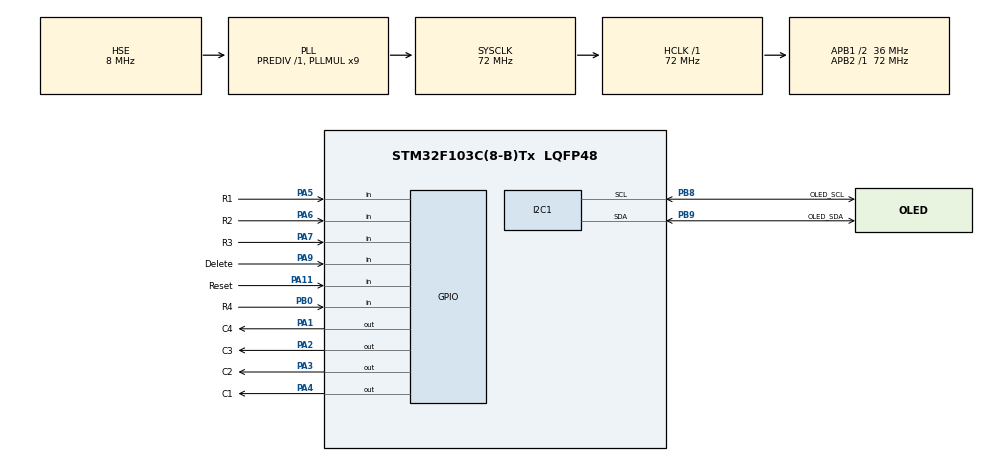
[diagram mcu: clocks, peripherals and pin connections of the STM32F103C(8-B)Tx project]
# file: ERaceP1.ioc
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I2C1.I2C_Mode=I2C_Fast
Mcu.Family=STM32F1
Mcu.Name=STM32F103C(8-B)Tx
Mcu.Package=LQFP48
NVIC.PriorityGroup=NVIC_PRIORITYGROUP_4
PA1.GPIO_Label=C4
PA1.GPIO_Speed=GPIO_SPEED_FREQ_HIGH
PA1.PinState=GPIO_PIN_SET
PA1.Signal=GPIO_Output
PA11.GPIO_Label=Reset
PA11.GPIO_PuPd=GPIO_PULLDOWN
PA11.Signal=GPIO_Input
PA13.Mode=Serial_Wire
PA13.Signal=SYS_JTMS-SWDIO
PA14.Mode=Serial_Wire
PA14.Signal=SYS_JTCK-SWCLK
PA2.GPIO_Label=C3
PA2.GPIO_Speed=GPIO_SPEED_FREQ_HIGH
PA2.PinState=GPIO_PIN_SET
PA2.Signal=GPIO_Output
PA3.GPIO_Label=C2
PA3.GPIO_Speed=GPIO_SPEED_FREQ_HIGH
PA3.PinState=GPIO_PIN_SET
PA3.Signal=GPIO_Output
PA4.GPIO_Label=C1
PA4.GPIO_Speed=GPIO_SPEED_FREQ_HIGH
PA4.PinState=GPIO_PIN_SET
PA4.Signal=GPIO_Output
PA5.GPIO_Label=R1
PA5.GPIO_PuPd=GPIO_PULLUP
PA5.Signal=GPIO_Input
PA6.GPIO_Label=R2
PA6.GPIO_PuPd=GPIO_PULLUP
PA6.Signal=GPIO_Input
PA7.GPIO_Label=R3
PA7.GPIO_PuPd=GPIO_PULLUP
PA7.Signal=GPIO_Input
PA9.GPIO_Label=Delete
PA9.GPIO_PuPd=GPIO_PULLDOWN
PA9.Signal=GPIO_Input
PB0.GPIO_Label=R4
PB0.GPIO_PuPd=GPIO_PULLUP
PB0.Signal=GPIO_Input
PB8.GPIO_Label=OLED_SCL
PB8.Mode=I2C
PB8.Signal=I2C1_SCL
PB9.GPIO_Label=OLED_SDA
PB9.Mode=I2C
PB9.Signal=I2C1_SDA
PC14-OSC32_IN.Mode=LSE-External-Oscillator
PC14-OSC32_IN.Signal=RCC_OSC32_IN
PC15-OSC32_OUT.Mode=LSE-External-Oscillator
PC15-OSC32_OUT.Signal=RCC_OSC32_OUT
PD0-OSC_IN.Mode=HSE-External-Oscillator
PD0-OSC_IN.Signal=RCC_OSC_IN
PD1-OSC_OUT.Mode=HSE-External-Oscillator
PD1-OSC_OUT.Signal=RCC_OSC_OUT
ProjectManager.HeapSize=0x200
ProjectManager.StackSize=0x400
ProjectManager.TargetToolchain=STM32CubeIDE
RCC.AHBFreq_Value=72000000
RCC.APB1CLKDivider=RCC_HCLK_DIV2
RCC.APB1Freq_Value=36000000
RCC.APB1TimFreq_Value=72000000
RCC.APB2Freq_Value=72000000
RCC.APB2TimFreq_Value=72000000
RCC.HCLKFreq_Value=72000000
RCC.PLLMUL=RCC_PLL_MUL9
RCC.PLLSourceVirtual=RCC_PLLSOURCE_HSE
RCC.SYSCLKFreq_VALUE=72000000
RCC.SYSCLKSource=RCC_SYSCLKSOURCE_PLLCLK
RCC.USBFreq_Value=72000000
board=custom

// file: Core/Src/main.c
/* USER CODE BEGIN Header */
/**
  ******************************************************************************
  * @file           : main.c
  * @brief          : Main program body
  ******************************************************************************
  * @attention
  *
  * Copyright (c) 2023 STMicroelectronics.
  * All rights reserved.
  *
  * This software is licensed under terms that can be found in the LICENSE file
  * in the root directory of this software component.
  * If no LICENSE file comes with this software, it is provided AS-IS.
  *
  ******************************************************************************
  */
/* USER CODE END Header */
#include "main.h"
#include "i2c.h"
#include "gpio.h"

/* USER CODE BEGIN Includes */
#include "MatrixKey.h"
#include "handler.h"
#include "show.h"
/* USER CODE END Includes */

void SystemClock_Config(void);

int main(void)
{

  /* MCU Configuration--------------------------------------------------------*/

  /* Reset of all peripherals, Initializes the Flash interface and the Systick. */
  HAL_Init();

  /* Configure the system clock */
  SystemClock_Config();

  /* Initialize all configured peripherals */
  MX_GPIO_Init();
  MX_I2C1_Init();
  /* USER CODE BEGIN 2 */
    showInit();
    uint8_t p;
    p = 0;
    uint8_t handle[49]={};
  /* USER CODE END 2 */

  /* Infinite loop */
  while (1)
  {

    /* USER CODE BEGIN 3 */
    uint8_t tmp=0;
    tmp = ScanKey();
    handler(tmp,&p,handle);
  }
  /* USER CODE END 3 */
}

void SystemClock_Config(void)
{
  RCC_OscInitTypeDef RCC_OscInitStruct = {0};
  RCC_ClkInitTypeDef RCC_ClkInitStruct = {0};

  /** Initializes the RCC Oscillators according to the specified parameters
  * in the RCC_OscInitTypeDef structure.
  */
  RCC_OscInitStruct.OscillatorType = RCC_OSCILLATORTYPE_HSE;
  RCC_OscInitStruct.HSEState = RCC_HSE_ON;
  RCC_OscInitStruct.HSEPredivValue = RCC_HSE_PREDIV_DIV1;
  RCC_OscInitStruct.HSIState = RCC_HSI_ON;
  RCC_OscInitStruct.PLL.PLLState = RCC_PLL_ON;
  RCC_OscInitStruct.PLL.PLLSource = RCC_PLLSOURCE_HSE;
  RCC_OscInitStruct.PLL.PLLMUL = RCC_PLL_MUL9;
  if (HAL_RCC_OscConfig(&RCC_OscInitStruct) != HAL_OK)
  {
    Error_Handler();
  }

  /** Initializes the CPU, AHB and APB buses clocks
  */
  RCC_ClkInitStruct.ClockType = RCC_CLOCKTYPE_HCLK|RCC_CLOCKTYPE_SYSCLK
                              |RCC_CLOCKTYPE_PCLK1|RCC_CLOCKTYPE_PCLK2;
  RCC_ClkInitStruct.SYSCLKSource = RCC_SYSCLKSOURCE_PLLCLK;
  RCC_ClkInitStruct.AHBCLKDivider = RCC_SYSCLK_DIV1;
  RCC_ClkInitStruct.APB1CLKDivider = RCC_HCLK_DIV2;
  RCC_ClkInitStruct.APB2CLKDivider = RCC_HCLK_DIV1;

  if (HAL_RCC_ClockConfig(&RCC_ClkInitStruct, FLASH_LATENCY_2) != HAL_OK)
  {
    Error_Handler();
  }
}

void Error_Handler(void)
{
  __disable_irq();
  while (1)
  {
  }
}
